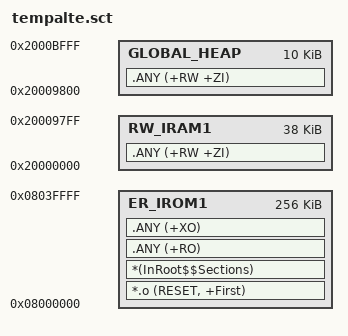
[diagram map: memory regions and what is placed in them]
; *************************************************************
; *** Scatter-Loading Description File generated by uVision ***
; *************************************************************

LR_IROM1 0x08000000 0x00040000  {    ; load region size_region
  ER_IROM1 0x08000000 0x00040000  {  ; load address = execution address
   *.o (RESET, +First)
   *(InRoot$$Sections)
   .ANY (+RO)
   .ANY (+XO)
  }
  RW_IRAM1 0x20000000 0x00009800  {  ; RW data
   .ANY (+RW +ZI)
  }
  
  GLOBAL_HEAP 0x20009800 0x00002800  {  ; RW data
   .ANY (+RW +ZI)
  }
}

